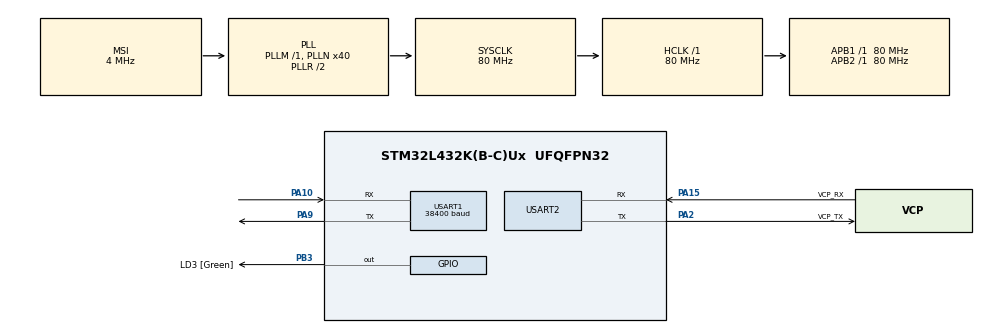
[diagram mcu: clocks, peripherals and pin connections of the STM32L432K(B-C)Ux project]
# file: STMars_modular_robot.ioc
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Dma.Request0=USART1_RX
Dma.Request1=USART1_TX
Dma.USART1_RX.0.Direction=DMA_PERIPH_TO_MEMORY
Dma.USART1_RX.0.Instance=DMA1_Channel5
Dma.USART1_RX.0.MemDataAlignment=DMA_MDATAALIGN_BYTE
Dma.USART1_RX.0.MemInc=DMA_MINC_ENABLE
Dma.USART1_RX.0.Mode=DMA_NORMAL
Dma.USART1_RX.0.PeriphDataAlignment=DMA_PDATAALIGN_BYTE
Dma.USART1_RX.0.PeriphInc=DMA_PINC_DISABLE
Dma.USART1_RX.0.Priority=DMA_PRIORITY_LOW
Dma.USART1_TX.1.Direction=DMA_MEMORY_TO_PERIPH
Dma.USART1_TX.1.Instance=DMA1_Channel4
Dma.USART1_TX.1.MemDataAlignment=DMA_MDATAALIGN_BYTE
Dma.USART1_TX.1.MemInc=DMA_MINC_ENABLE
Dma.USART1_TX.1.Mode=DMA_NORMAL
Dma.USART1_TX.1.PeriphDataAlignment=DMA_PDATAALIGN_BYTE
Dma.USART1_TX.1.PeriphInc=DMA_PINC_DISABLE
Dma.USART1_TX.1.Priority=DMA_PRIORITY_LOW
Mcu.Family=STM32L4
Mcu.Name=STM32L432K(B-C)Ux
Mcu.Package=UFQFPN32
NVIC.DMA1_Channel4_IRQn=true\:0\:0\:false\:true\:true\:3\:false\:true
NVIC.DMA1_Channel5_IRQn=true\:0\:0\:false\:true\:true\:2\:false\:true
NVIC.PriorityGroup=NVIC_PRIORITYGROUP_4
NVIC.USART1_IRQn=true\:0\:0\:false\:true\:true\:1\:true\:true
PA0.GPIO_Label=MCO [High speed clock in]
PA0.Mode=HSE-External-Clock-Source-for-LittleOrca
PA0.Signal=RCC_CK_IN
PA10.Mode=Asynchronous
PA10.Signal=USART1_RX
PA13\ (JTMS-SWDIO).GPIO_Label=SWDIO
PA13\ (JTMS-SWDIO).Mode=Serial_Wire
PA13\ (JTMS-SWDIO).Signal=SYS_JTMS-SWDIO
PA14\ (JTCK-SWCLK).GPIO_Label=SWCLK
PA14\ (JTCK-SWCLK).Mode=Serial_Wire
PA14\ (JTCK-SWCLK).Signal=SYS_JTCK-SWCLK
PA15\ (JTDI).GPIO_Label=VCP_RX
PA15\ (JTDI).Mode=Asynchronous
PA15\ (JTDI).Signal=USART2_RX
PA2.GPIO_Label=VCP_TX
PA2.Mode=Asynchronous
PA2.Signal=USART2_TX
PA9.Mode=Asynchronous
PA9.Signal=USART1_TX
PB3\ (JTDO-TRACESWO).GPIO_Label=LD3 [Green]
PB3\ (JTDO-TRACESWO).Signal=GPIO_Output
PC14-OSC32_IN\ (PC14).Mode=LSE-External-Oscillator
PC14-OSC32_IN\ (PC14).Signal=RCC_OSC32_IN
PC15-OSC32_OUT\ (PC15).Mode=LSE-External-Oscillator
PC15-OSC32_OUT\ (PC15).Signal=RCC_OSC32_OUT
ProjectManager.HeapSize=0x200
ProjectManager.StackSize=0x400
ProjectManager.TargetToolchain=STM32CubeIDE
RCC.AHBFreq_Value=80000000
RCC.APB1Freq_Value=80000000
RCC.APB1TimFreq_Value=80000000
RCC.APB2Freq_Value=80000000
RCC.APB2TimFreq_Value=80000000
RCC.CortexFreq_Value=80000000
RCC.HCLKFreq_Value=80000000
RCC.HSE_VALUE=8000000
RCC.HSI16_VALUE=16000000
RCC.HSI48_VALUE=48000000
RCC.HSI_VALUE=16000000
RCC.MSI_VALUE=4000000
RCC.PLLMUL=RCC_PLLMUL_4
RCC.PLLN=40
RCC.SYSCLKFreq_VALUE=80000000
RCC.SYSCLKSource=RCC_SYSCLKSOURCE_PLLCLK
RCC.VCOOutputFreq_Value=160000000
USART1.BaudRate=38400
USART1.VirtualMode-Asynchronous=VM_ASYNC
USART2.VirtualMode-Asynchronous=VM_ASYNC
board=NUCLEO-L432KC

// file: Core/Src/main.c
/* USER CODE BEGIN Header */
/**
  ******************************************************************************
  * @file           : main.c
  * @brief          : Main program body
  * @author			: grados73
  * @project		: STMars_modular_robot
  */
/* USER CODE END Header */
#include "main.h"
#include "dma.h"
#include "usart.h"
#include "gpio.h"

/* USER CODE BEGIN Includes */

#include "parser.h"
/* USER CODE END Includes */

/* USER CODE BEGIN PV */
UARTDMA_HandleTypeDef huartdma1;
uint8_t BufferReceive[64];
/* USER CODE END PV */

void SystemClock_Config(void);
static void MX_NVIC_Init(void);

int main(void)
{

  /* MCU Configuration--------------------------------------------------------*/

  /* Reset of all peripherals, Initializes the Flash interface and the Systick. */
  HAL_Init();

  /* Configure the system clock */
  SystemClock_Config();

  /* Initialize all configured peripherals */
  MX_GPIO_Init();
  MX_DMA_Init();
  MX_USART2_UART_Init();
  MX_USART1_UART_Init();

  /* Initialize interrupts */
 // MX_NVIC_Init();
  /* USER CODE BEGIN 2 */
  UARTDMA_Init(&huartdma1, &huart1);
  /* USER CODE END 2 */

  /* Infinite loop */
  /* USER CODE BEGIN WHILE */
  while (1)
  {
	  //
	  	  // RECEIVE
	  	  //
	  	  if(UARTDM A_IsDataReceivedReady(&huartdma1))
	  	  {
	  		  UART_ParseLine(&huartdma1); // Parsing function
	  	  }

	  	  //
	  	  // TRANSMIT
	  	  //
	//  	  UARTDMA_TransmitEvent(&huartdma1);
    /* USER CODE END WHILE */

  }
}

void SystemClock_Config(void)
{
  RCC_OscInitTypeDef RCC_OscInitStruct = {0};
  RCC_ClkInitTypeDef RCC_ClkInitStruct = {0};
  RCC_PeriphCLKInitTypeDef PeriphClkInit = {0};

  /** Configure LSE Drive Capability
  */
  HAL_PWR_EnableBkUpAccess();
  __HAL_RCC_LSEDRIVE_CONFIG(RCC_LSEDRIVE_LOW);
  /** Initializes the RCC Oscillators according to the specified parameters
  * in the RCC_OscInitTypeDef structure.
  */
  RCC_OscInitStruct.OscillatorType = RCC_OSCILLATORTYPE_LSE|RCC_OSCILLATORTYPE_MSI;
  RCC_OscInitStruct.LSEState = RCC_LSE_ON;
  RCC_OscInitStruct.MSIState = RCC_MSI_ON;
  RCC_OscInitStruct.MSICalibrationValue = 0;
  RCC_OscInitStruct.MSIClockRange = RCC_MSIRANGE_6;
  RCC_OscInitStruct.PLL.PLLState = RCC_PLL_ON;
  RCC_OscInitStruct.PLL.PLLSource = RCC_PLLSOURCE_MSI;
  RCC_OscInitStruct.PLL.PLLM = 1;
  RCC_OscInitStruct.PLL.PLLN = 40;
  RCC_OscInitStruct.PLL.PLLP = RCC_PLLP_DIV7;
  RCC_OscInitStruct.PLL.PLLQ = RCC_PLLQ_DIV2;
  RCC_OscInitStruct.PLL.PLLR = RCC_PLLR_DIV2;
  if (HAL_RCC_OscConfig(&RCC_OscInitStruct) != HAL_OK)
  {
    Error_Handler();
  }
  /** Initializes the CPU, AHB and APB buses clocks
  */
  RCC_ClkInitStruct.ClockType = RCC_CLOCKTYPE_HCLK|RCC_CLOCKTYPE_SYSCLK
                              |RCC_CLOCKTYPE_PCLK1|RCC_CLOCKTYPE_PCLK2;
  RCC_ClkInitStruct.SYSCLKSource = RCC_SYSCLKSOURCE_PLLCLK;
  RCC_ClkInitStruct.AHBCLKDivider = RCC_SYSCLK_DIV1;
  RCC_ClkInitStruct.APB1CLKDivider = RCC_HCLK_DIV1;
  RCC_ClkInitStruct.APB2CLKDivider = RCC_HCLK_DIV1;

  if (HAL_RCC_ClockConfig(&RCC_ClkInitStruct, FLASH_LATENCY_4) != HAL_OK)
  {
    Error_Handler();
  }
  PeriphClkInit.PeriphClockSelection = RCC_PERIPHCLK_USART1|RCC_PERIPHCLK_USART2;
  PeriphClkInit.Usart1ClockSelection = RCC_USART1CLKSOURCE_PCLK2;
  PeriphClkInit.Usart2ClockSelection = RCC_USART2CLKSOURCE_PCLK1;
  if (HAL_RCCEx_PeriphCLKConfig(&PeriphClkInit) != HAL_OK)
  {
    Error_Handler();
  }
  /** Configure the main internal regulator output voltage
  */
  if (HAL_PWREx_ControlVoltageScaling(PWR_REGULATOR_VOLTAGE_SCALE1) != HAL_OK)
  {
    Error_Handler();
  }
  /** Enable MSI Auto calibration
  */
  HAL_RCCEx_EnableMSIPLLMode();
}

/**
  * @brief NVIC Configuration.
  * @retval None
  */
static void MX_NVIC_Init(void)
{
  /* USART1_IRQn interrupt configuration */
  HAL_NVIC_SetPriority(USART1_IRQn, 0, 0);
  HAL_NVIC_EnableIRQ(USART1_IRQn);
  /* DMA1_Channel5_IRQn interrupt configuration */
  HAL_NVIC_SetPriority(DMA1_Channel5_IRQn, 0, 0);
  HAL_NVIC_EnableIRQ(DMA1_Channel5_IRQn);
  /* DMA1_Channel4_IRQn interrupt configuration */
  HAL_NVIC_SetPriority(DMA1_Channel4_IRQn, 0, 0);
  HAL_NVIC_EnableIRQ(DMA1_Channel4_IRQn);
}

void Error_Handler(void)
{
  __disable_irq();
  while (1)
  {
  }
}

/************************ (C) COPYRIGHT STMicroelectronics *****END OF FILE****/
